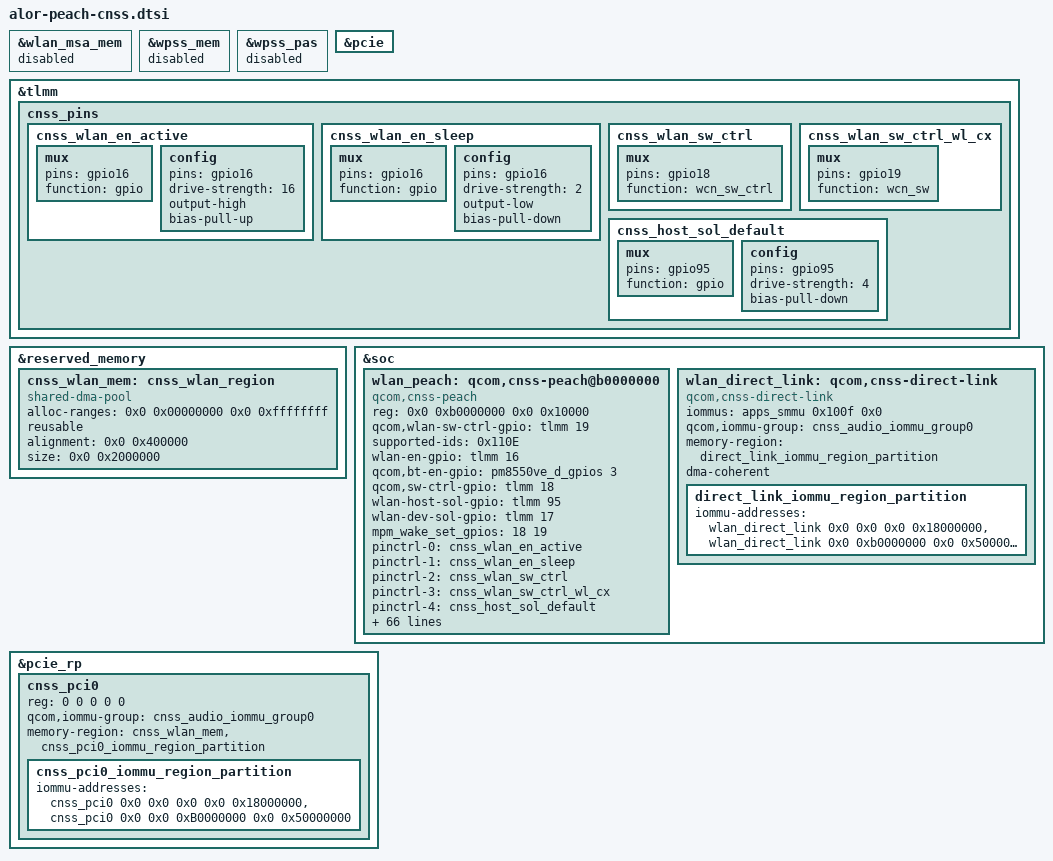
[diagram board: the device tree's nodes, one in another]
// SPDX-License-Identifier: BSD-3-Clause

/*
 * Copyright (c) Qualcomm Technologies, Inc. and/or its subsidiaries.
 */

#include <dt-bindings/interconnect/qcom,alor.h>

&wlan_msa_mem {
	status = "disabled";
};

&wpss_mem {
	status = "disabled";
};

&wpss_pas {
	status = "disabled";
};

&pcie {
	status = "ok";
};

&tlmm {
	cnss_pins {
		cnss_wlan_en_active: cnss_wlan_en_active {
			mux {
				pins = "gpio16";
				function = "gpio";
			};

			config {
				pins = "gpio16";
				drive-strength = <16>;
				output-high;
				bias-pull-up;
			};
		};

		cnss_wlan_en_sleep: cnss_wlan_en_sleep {
			mux {
				pins = "gpio16";
				function = "gpio";
			};

			config {
				pins = "gpio16";
				drive-strength = <2>;
				output-low;
				bias-pull-down;
			};
		};

		cnss_wlan_sw_ctrl: cnss_wlan_sw_ctrl {
			mux {
				pins = "gpio18";
				function = "wcn_sw_ctrl";
			};
		};

		cnss_wlan_sw_ctrl_wl_cx: cnss_wlan_sw_ctrl_wl_cx {
			mux {
				pins = "gpio19";
				function = "wcn_sw";
			};
		};

		cnss_host_sol_default: cnss_host_sol_default {
			mux {
				pins = "gpio95";
				function = "gpio";
			};

			config {
				pins = "gpio95";
				drive-strength = <4>;
				bias-pull-down;
			};
		};
	};
};

&reserved_memory {
	cnss_wlan_mem: cnss_wlan_region {
		compatible = "shared-dma-pool";
		alloc-ranges = <0x0 0x00000000 0x0 0xffffffff>;
		reusable;
		alignment = <0x0 0x400000>;
		size = <0x0 0x2000000>;
	};
};

&soc {
	wlan_peach: qcom,cnss-peach@b0000000 {
		compatible = "qcom,cnss-peach";
		reg = <0x0 0xb0000000 0x0 0x10000>;
		reg-names = "smmu_iova_ipa";
		qcom,wlan-sw-ctrl-gpio = <&tlmm 19 0>;

		supported-ids = <0x110E>;
		wlan-en-gpio = <&tlmm 16 0>;
		qcom,bt-en-gpio = <&pm8550ve_d_gpios 3 0>;
		qcom,sw-ctrl-gpio = <&tlmm 18 0>;
		wlan-host-sol-gpio = <&tlmm 95 0>;
		wlan-dev-sol-gpio = <&tlmm 17 0>;
		/* List of GPIOs to be setup for interrupt wakeup capable */
		mpm_wake_set_gpios = <18 19>;
		pinctrl-names = "wlan_en_active", "wlan_en_sleep", "sw_ctrl",
				"sw_ctrl_wl_cx", "sol_default";
		pinctrl-0 = <&cnss_wlan_en_active>;
		pinctrl-1 = <&cnss_wlan_en_sleep>;
		pinctrl-2 = <&cnss_wlan_sw_ctrl>;
		pinctrl-3 = <&cnss_wlan_sw_ctrl_wl_cx>;
		pinctrl-4 = <&cnss_host_sol_default>;
		qcom,wlan;
		qcom,wlan-rc-num = <0>;
		qcom,wlan-ramdump-dynamic = <0x780000>;
		cnss-enable-self-recovery;
		qcom,wlan-cbc-enabled;
		use-pm-domain;
		qcom,same-dt-multi-dev;
		/* For AOP communication, use direct QMP instead of mailbox */
		qcom,qmp = <&aoss_qmp>;
		platform-name-required;

		vdd-wlan-aon-supply = <&L2D>;
		qcom,vdd-wlan-aon-config = <1800000 1800000 0 0 1>;
		vdd-wlan-io12-supply = <&L3D>;
		qcom,vdd-wlan-io12-config = <1200000 1200000 0 0 1>;
		vdd-wlan-cx-supply = <&S3D>;
		qcom,vdd-wlan-cx-config = <412000 892000 0 0 1>;
		vdd-wlan-dig-supply = <&S1L>;
		qcom,vdd-wlan-dig-config = <700000 1352000 0 0 1>;
		vdd-wlan-rfa1-supply = <&S4D>;
		qcom,vdd-wlan-rfa1-config = <1876000 2100000 0 0 1>;
		vdd-wlan-rfa2-supply = <&S4F>;
		qcom,vdd-wlan-rfa2-config = <1328000 1400000 0 0 1>;
		vdd-wlan-ant-share-supply = <&L3K>;
		qcom,vdd-wlan-ant-share-config = <1200000 1200000 25 0 1>;

		interconnects =
		<&pcie_anoc MASTER_PCIE_0 &pcie_anoc SLAVE_ANOC_PCIE_GEM_NOC>,
		<&gem_noc MASTER_ANOC_PCIE_GEM_NOC &mc_virt SLAVE_EBI1>;
		interconnect-names = "pcie_to_memnoc", "memnoc_to_ddr";

		qcom,icc-path-count = <2>;
		qcom,bus-bw-cfg-count = <9>;
		qcom,bus-bw-cfg =
		/** ICC Path 1 **/
		<0 0>, /* no vote */
		/* idle: 0-18 Mbps snoc/anoc: 100 Mhz */
		<2250 2160000>,
		/* low: 18-60 Mbps snoc/anoc: 100 Mhz */
		<7500 2160000>,
		/* medium: 60-240 Mbps snoc/anoc: 100 Mhz */
		<30000 2160000>,
		/* high: 240-1200 Mbps snoc/anoc: 100 Mhz */
		<100000 2160000>,
		/* very high: 1200-2000 Mbps snoc/anoc: 100 Mhz */
		<250000 2160000>,
		/* ultra high: DBS mode snoc/anoc: 200 Mhz */
		<312500 2800000>,
		/* super high: DBS mode snoc/anoc: 403 Mhz */
		<587500 5624000>,
		/* low (latency critical): 18-60 Mbps snoc/anoc: 200 Mhz */
		<7500 1610000>,

		/** ICC Path 2 **/
		<0 0>,
		/* idle: 0-18 Mbps ddr: 547.2 MHz */
		<2250 1200000>,
		/* low: 18-60 Mbps ddr: 547.2 MHz */
		<7500 1200000>,
		/* medium: 60-240 Mbps ddr: 547.2 MHz */
		<30000 1200000>,
		/* high: 240-1200 Mbps ddr: 547.2 MHz */
		<100000 1200000>,
		/* very high: 1200-2000 Mbps ddr: 547.2 MHz */
		<250000 1200000>,
		/* ultra high: DBS mode ddr: 2092 MHz */
		<312500 8395000>,
		/* super high: DBS mode ddr: 3.2 GHz */
		<587500 13000000>,
		/* low (latency critical): 18-60 Mbps ddr: 547.2 MHz */
		<7500 2188800>;

		qcom,vreg_pdc_map =
			"S3D0", "bb",
			"S1L0", "rf",
			"S4D0", "rf",
			"S4F0", "rf";

		qcom,pmu_vreg_map =
			"VDDD_AON_0P9", "S1L0",
			"VDDA_RFA_0P9", "S1L0",
			"VDDA_RFA_1P9", "S4D0",
			"VDDA_RFA_1P3", "S4F0",
			"VDDD_WLMX_0P9", "S1L0",
			"VDDD_WLCX_0P9", "S3D0",
			"VDDD_BTCX_0P9", "S1L0",
			"VDDD_BTCMX_0P9", "S1L0",
			"VDDA_PCIE_0P9", "S4F0",
			"VDDA_PCIE_1P2", "S4F0";

		 qcom,pdc_init_table =
			 " {class: wlan_pdc, ss: rf, res: S4F0.v, upval: 1312}",
			 " {class: wlan_pdc, ss: rf, res: S4F0.v, dwnval: 1244}",
			 " {class: wlan_pdc, ss: rf, res: S4D0.v, upval: 1860}",
			 " {class: wlan_pdc, ss: rf, res: S4D0.v, dwnval: 1820}",
			 " {class: wlan_pdc, ss: rf, res: S2D0.m, enable: 0}",
			 " {class: wlan_pdc, ss: rf, res: S2D0.v, enable: 0}",
			 " {class: wlan_pdc, ss: rf, res: L16B0.m, enable: 0}",
			 " {class: wlan_pdc, ss: rf, res: B1B0.m, enable: 0}",
			 " {class: wlan_pdc, ss: rf, res: S1L0.m, enable: 1}",
			 " {class: wlan_pdc, ss: rf, res: S1L0.v, enable: 1}",
			 " {class: wlan_pdc, ss: bb, res: pdc, enable: 1}";

		/* cpu mask used for wlan tx rx interrupt affinity
		 * <cpumask_for_rx_interrupts cpumask_for_tx_comp_interrupts>
		 */
		wlan-txrx-intr-cpumask = <0x3 0x30>;

		/* PMIC reg & regulator for XOCAL purpose
		 */
		nvmem-cells = <&xo_calib_data>;
		nvmem-cell-names = "xo_calib_reg";
		wcal-pbs-supply = <&WCAL_PBS>;
	};

	wlan_direct_link: qcom,cnss-direct-link {
		compatible = "qcom,cnss-direct-link";
		#address-cells = <2>;
		#size-cells = <2>;
		iommus = <&apps_smmu 0x100f 0x0>;
		qcom,iommu-group = <&cnss_audio_iommu_group0>;
		memory-region = <&direct_link_iommu_region_partition>;
		dma-coherent;

		direct_link_iommu_region_partition: direct_link_iommu_region_partition {
			iommu-addresses = <&wlan_direct_link 0x0 0x0 0x0 0x18000000>,
				<&wlan_direct_link 0x0 0xb0000000 0x0 0x50000000>;
		};
	};
};

&pcie_rp {
	#address-cells = <3>;
	#size-cells = <2>;

	cnss_pci0: cnss_pci0 {
		reg = <0 0 0 0 0>;
		qcom,iommu-group = <&cnss_audio_iommu_group0>;
		memory-region = <&cnss_wlan_mem &cnss_pci0_iommu_region_partition>;
		cnss_pci0_iommu_region_partition: cnss_pci0_iommu_region_partition {
			/* address-cells =3 size-cells=2 from alor-pcie.dtsi */
			iommu-addresses = <&cnss_pci0 0x0 0x0 0x0 0x0 0x18000000>,
					  <&cnss_pci0 0x0 0x0 0xB0000000 0x0 0x50000000>;
		};
	};
};
